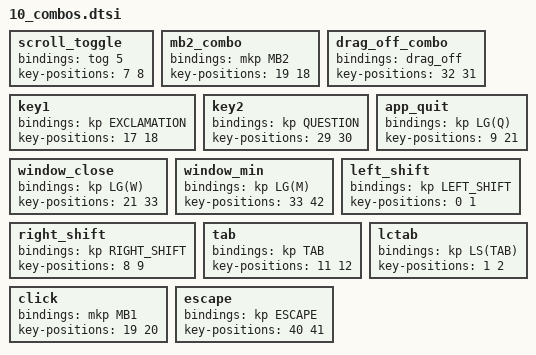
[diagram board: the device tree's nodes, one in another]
/* ============================================================
 * 10_combos.dtsi — コンボ定義
 *
 * combos { compatible = "zmk,combos"; } の内側でインクルードされる。
 * ============================================================ */

scroll_toggle {
    bindings = <&tog 5>;
    key-positions = <7 8>;
};

mb2_combo {
    bindings = <&mkp MB2>;
    key-positions = <19 18>;
};

drag_off_combo {
    bindings = <&drag_off>;
    key-positions = <32 31>;
};

key1 {
    bindings = <&kp EXCLAMATION>;
    key-positions = <17 18>;
};

key2 {
    bindings = <&kp QUESTION>;
    key-positions = <29 30>;
};

app_quit {
    bindings = <&kp LG(Q)>;
    key-positions = <9 21>;
};

window_close {
    bindings = <&kp LG(W)>;
    key-positions = <21 33>;
};

window_min {
    bindings = <&kp LG(M)>;
    key-positions = <33 42>;
};

left_shift {
    bindings = <&kp LEFT_SHIFT>;
    key-positions = <0 1>;
};

right_shift {
    bindings = <&kp RIGHT_SHIFT>;
    key-positions = <8 9>;
};

tab {
    bindings = <&kp TAB>;
    key-positions = <11 12>;
};

lctab {
    bindings = <&kp LS(TAB)>;
    key-positions = <1 2>;
};

click {
    bindings = <&mkp MB1>;
    key-positions = <19 20>;
};

escape {
    bindings = <&kp ESCAPE>;
    key-positions = <40 41>;
};
